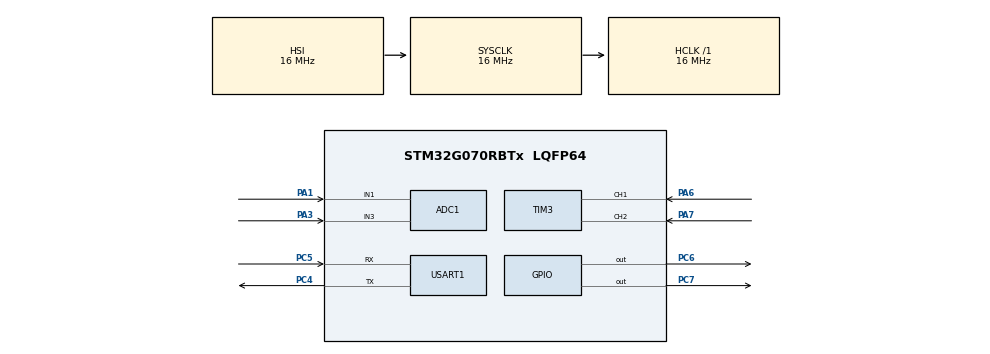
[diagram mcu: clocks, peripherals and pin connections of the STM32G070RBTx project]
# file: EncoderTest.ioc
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ADC1.Channel-2\#ChannelRegularConversion=ADC_CHANNEL_1
ADC1.Channel-3\#ChannelRegularConversion=ADC_CHANNEL_3
ADC1.ClockPrescaler=ADC_CLOCK_SYNC_PCLK_DIV4
ADC1.ContinuousConvMode=ENABLE
ADC1.NbrOfConversion=2
ADC1.NbrOfConversionFlag=1
ADC1.Rank-2\#ChannelRegularConversion=1
ADC1.Rank-3\#ChannelRegularConversion=2
ADC1.SamplingTime-2\#ChannelRegularConversion=ADC_SAMPLINGTIME_COMMON_1
ADC1.SamplingTime-3\#ChannelRegularConversion=ADC_SAMPLINGTIME_COMMON_1
ADC1.SamplingTimeCommon1=ADC_SAMPLETIME_7CYCLES_5
ADC1.SamplingTimeCommon2=ADC_SAMPLETIME_7CYCLES_5
ADC1.SelectedChannel=ADC_CHANNEL_1|ADC_CHANNEL_3
ADC1.master=1
Dma.ADC1.0.Direction=DMA_PERIPH_TO_MEMORY
Dma.ADC1.0.EventEnable=DISABLE
Dma.ADC1.0.Instance=DMA1_Channel1
Dma.ADC1.0.MemDataAlignment=DMA_MDATAALIGN_HALFWORD
Dma.ADC1.0.MemInc=DMA_MINC_ENABLE
Dma.ADC1.0.Mode=DMA_NORMAL
Dma.ADC1.0.PeriphDataAlignment=DMA_PDATAALIGN_HALFWORD
Dma.ADC1.0.PeriphInc=DMA_PINC_DISABLE
Dma.ADC1.0.Polarity=HAL_DMAMUX_REQ_GEN_RISING
Dma.ADC1.0.Priority=DMA_PRIORITY_LOW
Dma.ADC1.0.RequestNumber=1
Dma.ADC1.0.SignalID=NONE
Dma.ADC1.0.SyncEnable=DISABLE
Dma.ADC1.0.SyncPolarity=HAL_DMAMUX_SYNC_NO_EVENT
Dma.ADC1.0.SyncRequestNumber=1
Dma.ADC1.0.SyncSignalID=NONE
Dma.Request0=ADC1
Mcu.Family=STM32G0
Mcu.Name=STM32G070RBTx
Mcu.Package=LQFP64
NVIC.DMA1_Channel1_IRQn=true\:0\:0\:false\:false\:true\:false\:true\:true
PA1.Mode=IN1
PA1.Signal=ADC1_IN1
PA13.Mode=Serial_Wire
PA13.Signal=SYS_SWDIO
PA14-BOOT0.Mode=Serial_Wire
PA14-BOOT0.Signal=SYS_SWCLK
PA3.Mode=IN3
PA3.Signal=ADC1_IN3
PA6.GPIO_Speed=GPIO_SPEED_FREQ_VERY_HIGH
PA6.Signal=S_TIM3_CH1
PA7.GPIO_Speed=GPIO_SPEED_FREQ_VERY_HIGH
PA7.Signal=S_TIM3_CH2
PC4.Mode=Asynchronous
PC4.Signal=USART1_TX
PC5.Mode=Asynchronous
PC5.Signal=USART1_RX
PC6.Signal=GPIO_Output
PC7.Signal=GPIO_Output
ProjectManager.HeapSize=0x200
ProjectManager.StackSize=0x400
ProjectManager.TargetToolchain=STM32CubeIDE
RCC.AHBFreq_Value=16000000
RCC.CortexFreq_Value=16000000
RCC.EXTERNAL_CLOCK_VALUE=48000
RCC.HCLKFreq_Value=16000000
RCC.HSE_VALUE=8000000
RCC.HSI_VALUE=16000000
RCC.LSE_VALUE=32768
RCC.SYSCLKFreq_VALUE=16000000
RCC.VCOOutputFreq_Value=128000000
SH.S_TIM3_CH1.0=TIM3_CH1,Encoder_Interface
SH.S_TIM3_CH2.0=TIM3_CH2,Encoder_Interface
TIM3.AutoReloadPreload=TIM_AUTORELOAD_PRELOAD_ENABLE
TIM3.EncoderMode=TIM_ENCODERMODE_TI12
TIM3.IC1Filter=6
TIM3.IC2Filter=6
USART1.VirtualMode-Asynchronous=VM_ASYNC
VP_SYS_VS_DBSignals.Mode=DisableDeadBatterySignals
board=custom

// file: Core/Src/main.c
/* USER CODE BEGIN Header */
/**
  ******************************************************************************
  * @file           : main.c
  * @brief          : Main program body
  ******************************************************************************
  * @attention
  *
  * Copyright (c) 2023 STMicroelectronics.
  * All rights reserved.
  *
  * This software is licensed under terms that can be found in the LICENSE file
  * in the root directory of this software component.
  * If no LICENSE file comes with this software, it is provided AS-IS.
  *
  ******************************************************************************
  */
/* USER CODE END Header */
#include <stdio.h>
#include <stdbool.h>
#include "main.h"
#include "adc.h"
#include "dma.h"
#include "tim.h"
#include "usart.h"
#include "gpio.h"

/* USER CODE BEGIN PD */
uint16_t ADC_Volt=0;
uint16_t ADC_Value[2] = {0};
/* USER CODE END PD */

void SystemClock_Config(void);
/* USER CODE BEGIN PFP */
#ifdef __GNUC__
#define PUTCHAR_PROTOTYPE int __io_putchar(int ch)
#else
#define PUTCHAR_PROTOTYPE int fputc(int ch, FILE *f)
#endif

PUTCHAR_PROTOTYPE
{
    HAL_UART_Transmit(&huart1, (uint8_t *)&ch, 1, HAL_MAX_DELAY);
    return ch;
}
/* USER CODE END PFP */

int main(void)
{

  /* MCU Configuration--------------------------------------------------------*/

  /* Reset of all peripherals, Initializes the Flash interface and the Systick. */
  HAL_Init();

  /* Configure the system clock */
  SystemClock_Config();

  /* Initialize all configured peripherals */
  MX_GPIO_Init();
  MX_DMA_Init();
  MX_USART1_UART_Init();
  MX_TIM3_Init();
  MX_ADC1_Init();
  /* USER CODE BEGIN 2 */
  //使能编码器模式
  HAL_TIM_Encoder_Start(&htim3,TIM_CHANNEL_1);
  HAL_TIM_Encoder_Start(&htim3,TIM_CHANNEL_2);
  //编码器计数器复位
  __HAL_TIM_SET_COUNTER(&htim3,65000);
  //HAL_ADC_Start_DMA(hadc1,)
  /* USER CODE END 2 */

  /* Infinite loop */
  while (1)
  {
    //读取编码器当前的计数值，因为是四倍频，所以除以4才是真实的脉冲数
//    volatile uint32_t CaptureNumber = __HAL_TIM_GET_COUNTER(&htim3) / 4;
    //获取电机的转动方向，0为正、1为反
//    bool direction = __HAL_TIM_IS_TIM_COUNTING_DOWN(&htim3);
//      printf("{position}%d\n",CaptureNumber);
//      printf("{direction}%d\n",direction);
//      printf("{level}%d,%d\n", HAL_GPIO_ReadPin(GPIOA,GPIO_PIN_6),HAL_GPIO_ReadPin(GPIOA,GPIO_PIN_7));
//    HAL_Delay(100);

      //反转引脚
      HAL_GPIO_TogglePin(GPIOC,GPIO_PIN_6);
      HAL_Delay(50);
      HAL_GPIO_TogglePin(GPIOC,GPIO_PIN_7);
      HAL_Delay(50);
      HAL_Delay(1000);
      uint32_t CaptureNumber = __HAL_TIM_GET_COUNTER(&htim3);
      printf("{position}%d\n",CaptureNumber);

  }
}

void SystemClock_Config(void)
{
  RCC_OscInitTypeDef RCC_OscInitStruct = {0};
  RCC_ClkInitTypeDef RCC_ClkInitStruct = {0};

  /** Configure the main internal regulator output voltage
  */
  HAL_PWREx_ControlVoltageScaling(PWR_REGULATOR_VOLTAGE_SCALE1);

  /** Initializes the RCC Oscillators according to the specified parameters
  * in the RCC_OscInitTypeDef structure.
  */
  RCC_OscInitStruct.OscillatorType = RCC_OSCILLATORTYPE_HSI;
  RCC_OscInitStruct.HSIState = RCC_HSI_ON;
  RCC_OscInitStruct.HSIDiv = RCC_HSI_DIV1;
  RCC_OscInitStruct.HSICalibrationValue = RCC_HSICALIBRATION_DEFAULT;
  RCC_OscInitStruct.PLL.PLLState = RCC_PLL_NONE;
  if (HAL_RCC_OscConfig(&RCC_OscInitStruct) != HAL_OK)
  {
    Error_Handler();
  }

  /** Initializes the CPU, AHB and APB buses clocks
  */
  RCC_ClkInitStruct.ClockType = RCC_CLOCKTYPE_HCLK|RCC_CLOCKTYPE_SYSCLK
                              |RCC_CLOCKTYPE_PCLK1;
  RCC_ClkInitStruct.SYSCLKSource = RCC_SYSCLKSOURCE_HSI;
  RCC_ClkInitStruct.AHBCLKDivider = RCC_SYSCLK_DIV1;
  RCC_ClkInitStruct.APB1CLKDivider = RCC_HCLK_DIV1;

  if (HAL_RCC_ClockConfig(&RCC_ClkInitStruct, FLASH_LATENCY_0) != HAL_OK)
  {
    Error_Handler();
  }
}

void Error_Handler(void)
{
  __disable_irq();
  while (1)
  {
  }
}
